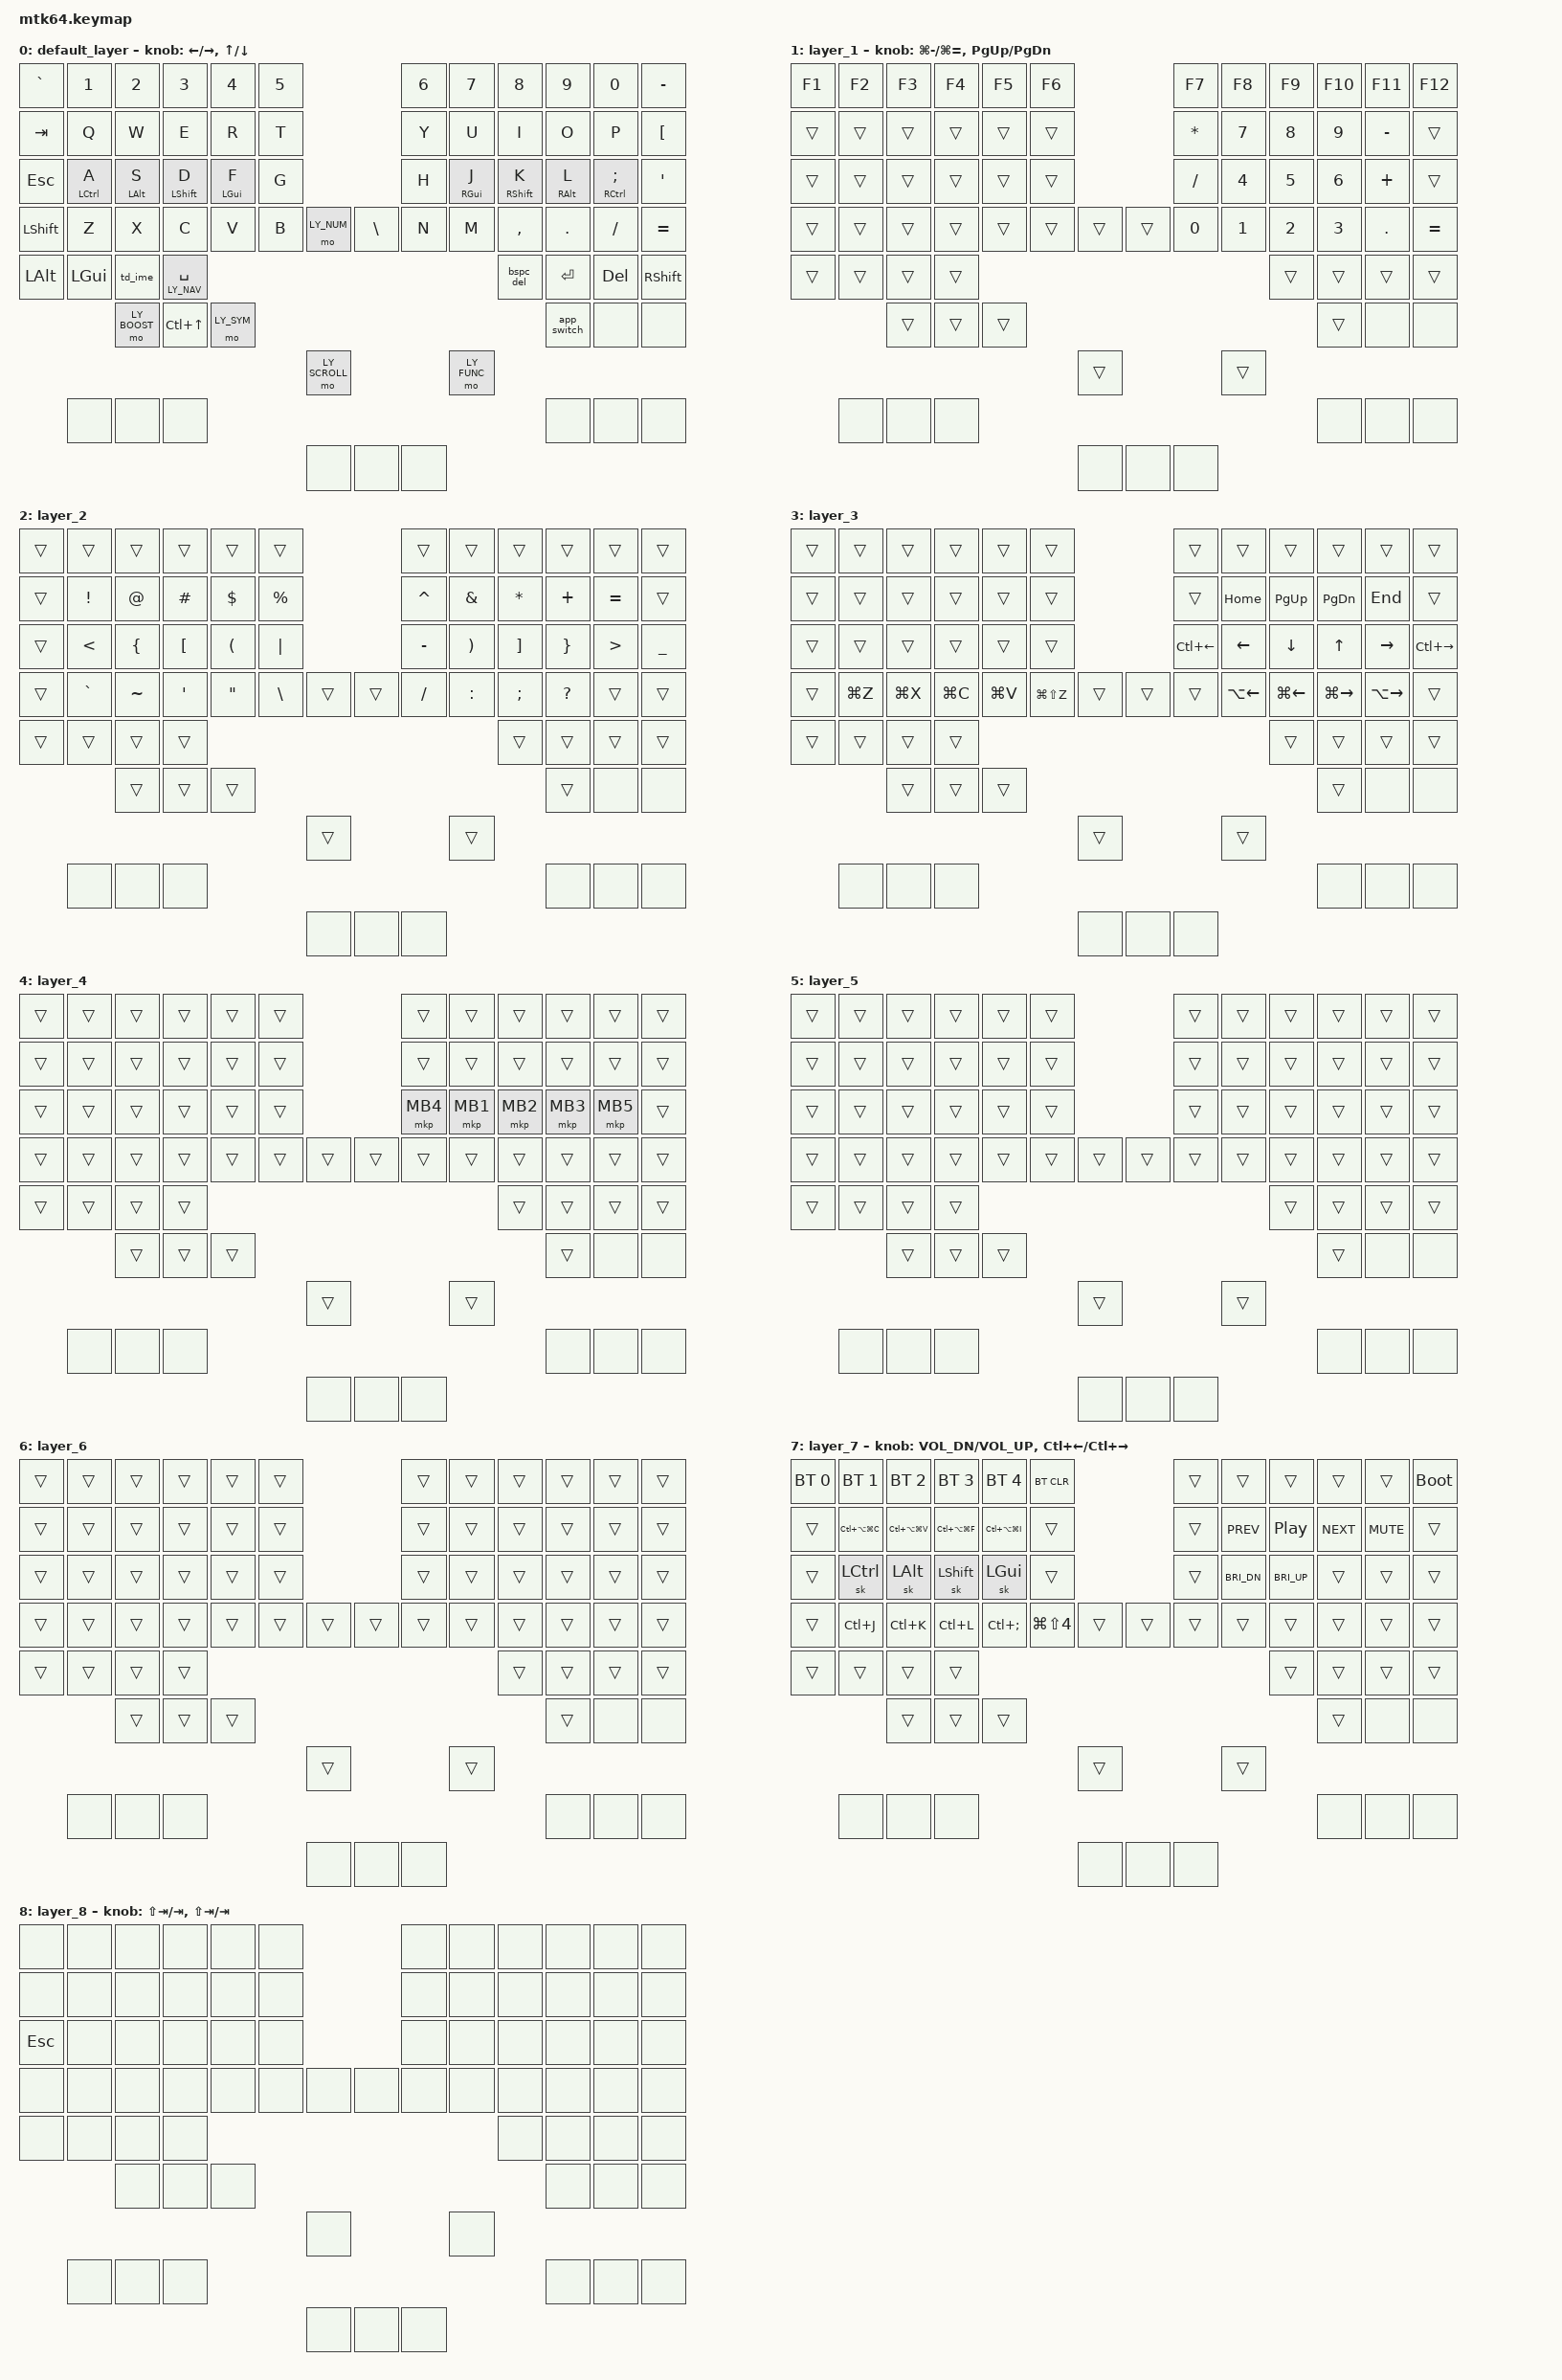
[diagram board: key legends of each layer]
// ポインタ既定値。dt-bindings/zmk/pointing.h の #include より「前」に置く必要がある。
// 後ろに書くと define が効かず、既定値 (MOVE=600 / SCRL=10) のままになる。
// 2026-08-13 まで9行目 (include の後ろ) にあったためスクロールが 10 で動いていた。
#define ZMK_POINTING_DEFAULT_MOVE_VAL 600
// SCRL_VAL は「1秒あたりのスクロール量」。エンコーダーは tap-ms 20ms 押す扱いなので
// 1目盛あたり SCRL_VAL × 0.02 が出る。100 なら 1目盛 = 2ノッチ。
// 800 も試したが速すぎたので戻した (2026-08-13)。
#define ZMK_POINTING_DEFAULT_SCRL_VAL 100

#include <behaviors.dtsi>
#include <dt-bindings/zmk/bt.h>
#include <dt-bindings/zmk/keys.h>
#include <dt-bindings/zmk/modifiers.h>
#include <dt-bindings/zmk/pointing.h>
#include <input/processors.dtsi>

// ============================================================
// レイヤー8枚 (2026-08-16, 工程2)
// 番号は mtk64_trackball.dtsi の zip_temp_layer / snipe / scroll とも一致させること。
// 片方だけ直すと、マウスもスクロールも精密モードも別のレイヤーを見にいく。
// ============================================================
#define LY_BASE   0
#define LY_NUM    1
#define LY_SYM    2
#define LY_NAV    3
#define LY_MOUSE  4
#define LY_SCROLL 5
#define LY_BOOST  6
#define LY_FUNC   7
#define LY_APPSW  8

&mt {
    flavor = "balanced";
    quick-tap-ms = <0>;
};

// マウスキーを押したときも自動マウスレイヤーに入る。番号は下の LY_MOUSE と同じ。
&mkp_input_listener {
    input-processors = <&zip_temp_layer LY_MOUSE 5000>;
};

/ {
    behaviors {
        // 垂直スクロール用のbehaviorの設定
        scroll_up_down: behavior_sensor_rotate_mouse_wheel_up_down {
            compatible = "zmk,behavior-sensor-rotate-var";
            #sensor-binding-cells = <2>;
            bindings = <&msc>, <&msc>;
            tap-ms = <20>; // スクロールのタップ時間
        };
        // 水平スクロール用のbehaviorの設定
        scroll_left_right: behavior_sensor_rotate_mouse_wheel_left_right {
            compatible = "zmk,behavior-sensor-rotate-var";
            #sensor-binding-cells = <2>;
            bindings = <&msc>, <&msc>;
            tap-ms = <20>; // スクロールのタップ時間
        };
    };
};

// ============================================================
// Home Row Mods (Phase 2-A, 2026-07-03 / 並びを 2026-08-13 に旧配列へ戻した) — urob流 timeless HRM
// 配列: 小指=Ctrl 薬指=Alt 中指=Shift 人差指=Cmd
//   (a=Ctrl s=Alt d=Shift f=Cmd / 右手ミラー j=Cmd k=Shift l=Alt ;=Ctrl)
//   Cmd+C/V/X/Z/A/S/W/T/F は文字がすべて左手にあり、バイラテラルでは必ず右手の Cmd を使う。
//   人差指 (J) に Cmd を置くと右手で最も強い指が使える。GACS では小指 (;) だった。
//   behavior のパラメータ (balanced / 280ms / 175ms / 150ms / バイラテラル) は変えていない。
// バイラテラル: hold-trigger-key-positions に「反対手 + 全親指」のみ列挙
//   → 同じ手のキーとの組合せでは自動的に tap 扱い (誤発火の構造的排除)
//
// require-prior-idle-ms = 150 の副作用: 直前150ms 以内に打鍵があると hold が発火せず tap になる。
//   つまり語中の大文字 (DX / FOB のような綴り) は HRM の Shift では打てない。
//   位置36 の物理 Shift を残してあるのはこの逃げ道のため。同じ理由で 50 (Alt) と 51 (Cmd) も残す
//   (Cmd+クリック / Shift+クリックは、HRM だと押しっぱなしが要るので物理キーのほうが確実)。
//   潰したのは位置24 の物理 Ctrl だけ。真下の a が HRM で Ctrl を持っていて完全に重複しており、
//   しかも Caps Lock 位置という一等地だったので Esc に回した (2026-08-16)。
//
// 物理の位置番号 (0起点、bindings 記載順):
//   Row1:  0-5   | 6-11      Row2: 12-17 | 18-23
//   Row3: 24-29  | 30-35     Row4: 36-42 | 43-49
//   Row5-7: 50-65             サイド/フット: 66-74
//   実在するキーは64個。名前の MTK64 と一致する。存在しないのは次の11か所:
//     58 / 59 = 左手のロータリーエンコーダー2個。押し込みは入力として使える (キーではない)
//     62 / 63 = トラックボール。キーが無いので押し込みも割り当てられない → &none
//     66-74   = 下端3キー×2・フットスイッチ3個。物理的に付いていない → &none
//   マトリクスの数だけは75個 合わせる必要がある。
// ============================================================
/ {
    behaviors {
        // 左手 HRM: 右手キー (6-11,18-23,30-35,43-49) + 親指 (50-65) とのみ hold 成立
        hml: homerow_mod_left {
            compatible = "zmk,behavior-hold-tap";
            #binding-cells = <2>;
            flavor = "balanced";
            tapping-term-ms = <280>;
            quick-tap-ms = <175>;
            require-prior-idle-ms = <150>;
            bindings = <&kp>, <&kp>;
            hold-trigger-key-positions = <6 7 8 9 10 11 18 19 20 21 22 23 30 31 32 33 34 35 43 44 45 46 47 48 49 50 51 52 53 54 55 56 57 58 59 60 61 62 63 64 65>;
            hold-trigger-on-release;
        };
        // 右手 HRM: 左手キー (0-5,12-17,24-29,36-42) + 親指 (50-65) とのみ hold 成立
        hmr: homerow_mod_right {
            compatible = "zmk,behavior-hold-tap";
            #binding-cells = <2>;
            flavor = "balanced";
            tapping-term-ms = <280>;
            quick-tap-ms = <175>;
            require-prior-idle-ms = <150>;
            bindings = <&kp>, <&kp>;
            hold-trigger-key-positions = <0 1 2 3 4 5 12 13 14 15 16 17 24 25 26 27 28 29 36 37 38 39 40 41 42 50 51 52 53 54 55 56 57 58 59 60 61 62 63 64 65>;
            hold-trigger-on-release;
        };

        // td_ime — 位置52。1タップ=英数 / 2タップ=かな (2026-08-16 に本人の希望で入れた)。
        //   ZMK の tap-dance は長押しを兼ねられない。bindings に <&lt_ime LY_SYM LANG2> を
        //   入れれば形は作れるが、tap-dance の200ms が解決してから hold-tap の180ms が
        //   始まるので、記号レイヤーに入るまで380ms かかる。入れ子にはしない。
        //   そのぶん SYM は位置60 の純粋な &mo に移した。長押し待ちが無くなるので、
        //   前の版で工程3送りにしていた「SYM に入るのに最大180ms」はこれで消えている。
        //
        //   1タップの確定は「tapping-term が切れる」か「別のキーが押される」かのどちらか早いほう。
        //   IME を切り替えたら必ず何か打つので、実際には次の1打鍵で即 確定する。
        //   200ms はダブルタップとみなす窓でもある。英数を2回 続けて叩くとかなになる点だけ注意。
        td_ime: tap_dance_ime {
            compatible = "zmk,behavior-tap-dance";
            #binding-cells = <0>;
            tapping-term-ms = <200>;
            bindings = <&kp LANG2>, <&kp LANG1>;
        };
        // lt_nav — Space (53)。Space は必ず文字の直後に来るので、require-prior-idle-ms が
        //   打鍵中の hold 誤発火を丸ごと止める。止まった後に押した時だけ balanced が効いて即座に
        //   NAV に入れる。矢印は連続して押すので、入るのが速いほうが得。
        lt_nav: layer_tap_nav {
            compatible = "zmk,behavior-hold-tap";
            #binding-cells = <2>;
            flavor = "balanced";
            tapping-term-ms = <200>;
            quick-tap-ms = <175>;
            require-prior-idle-ms = <150>;
            bindings = <&mo>, <&kp>;
        };

        // app_switch — 位置58 (外側のノブの押し込み)。Cmd+Tab のアプリ切替を
        //   ノブで送るためのもの (2026-08-16 の依頼)。押している間だけ Cmd を押しっぱなしにし、
        //   同時に LY_APPSW へ入る。そのレイヤーではエンコーダーが Tab / Shift+Tab を送るので、
        //   切替の一覧が開いたまま前にも後ろにも送れる。離すと Cmd が上がって確定する。
        //
        //   エンコーダーに直接 <&inc_dec_kp LG(LS(TAB)) LG(TAB)> を置くのでは駄目である。
        //   1目盛ごとに Cmd を離してしまうので、macOS はそのたびに切替を確定してしまい、
        //   一覧が開かない。2つのアプリを行ったり来たりするだけになる。
        //
        //   2026-08-17 に位置59 から58 へ移した。59 は Mission Control にしたため。
        //   押し込みながら回せるかは実機で確かめること。どちらのノブを回しても効くように、
        //   LY_APPSW ではエンコーダー2個に同じ割当を入れてある。
        //   型は ZMK 公式ドキュメント (keymaps/behaviors/macros) の「レイヤー + 修飾キー」そのもの。
        app_switch: app_switch {
            compatible = "zmk,behavior-macro";
            #binding-cells = <0>;
            wait-ms = <0>;
            tap-ms = <0>;
            bindings
                = <&macro_press &mo LY_APPSW &kp LGUI>
                , <&macro_pause_for_release>
                , <&macro_release &mo LY_APPSW &kp LGUI>;
        };

        // BkSp を Shift と一緒に押すと Delete (前方削除)。遅延ゼロ。
        // 位置56 にも独立した Delete を置いてあるので、どちらでも打てる。
        bspc_del: backspace_delete {
            compatible = "zmk,behavior-mod-morph";
            #binding-cells = <0>;
            bindings = <&kp BSPC>, <&kp DEL>;
            mods = <(MOD_LSFT|MOD_RSFT)>;
        };
    };

    // 句読点 combo — 旧 Studio カスタム (j長押し=、 k長押し=。 ;長押し=ー) の置換。
    // 長押し待ち (200ms) がなくなり同時押しで即入力。ローマ字入力で j+k / k+l / l+; の
    // ロールはほぼ発生しないため誤爆リスク低 (英語 "quickly" 等の k→l ロールだけ Week1 で観測)
    combos {
        compatible = "zmk,combos";
        combo_touten {
            timeout-ms = <30>;
            key-positions = <31 32>;    // J + K → 、
            bindings = <&kp COMMA>;
            layers = <0>;
        };
        combo_kuten {
            timeout-ms = <30>;
            key-positions = <32 33>;    // K + L → 。
            bindings = <&kp DOT>;
            layers = <0>;
        };
        combo_chouon {
            timeout-ms = <30>;
            key-positions = <33 34>;    // L + ; → ー
            bindings = <&kp MINUS>;
            layers = <0>;
        };
        // F + J で次の1語だけ大文字 (Caps Word)。Shift を押しっぱなしにしないで済む。
        // 左右にまたがるので同じ手のロールでは起きない。f→j / j→f はローマ字にも英語にも無い。
        combo_caps_word {
            timeout-ms = <30>;
            key-positions = <28 31>;    // F + J
            bindings = <&caps_word>;
            layers = <0>;
        };
    };
};

/ {

    keymap {
        compatible = "zmk,keymap";

        // ------------------------------------------------------------------
        // L0 BASE — US ANSI QWERTY + Home Row Mods
        //   0  : ` (バッククォート)。工程1 まで7レイヤー525キーのどこにも無かった字。
        //         Markdown のコードスパンで毎日使うので US ANSI の定位置に置いた。
        //   24 : Esc。Caps Lock 位置。日本語入力の変換取り消しで最も打つキーなので一等地に移した。
        //   49 : = 。工程1 まで死んでいた位置。右小指の外側の列が上から - [ ' = で揃う。
        //   56 : Delete (前方削除)。工程1 まで keymap 全体に1つも無かった。
        //   57 : 右手の物理 Shift。工程1 まで右半分には物理の修飾キーが1つも無かった。
        //         左手の文字を語中で大文字にする (DX / FOB) には右手の Shift が要るのに、
        //         HRM の k は require-prior-idle-ms で打鍵中は発火しない。50/51 の鏡の位置。
        //   54 : BkSp / Shift併用で Delete (mod-morph)。
        //   58 / 59 : ロータリーエンコーダーの押し込み (2026-08-17 に入れ替えた)。
        //         58 (外側) = アプリ切替。押したまま回すと Cmd+Tab の一覧を送れる (app_switch を見よ)。
        //         59 (内側) = Mission Control (Ctrl+↑)。本人の希望で入れた。
        //         ミュートはここから外したが FUNC の段1 (位置15) に残っている。
        //         Enter は 55 の右親指に1つ残っている。
        //   42 : NUM の呼び出し (左手人差指の内側)。親指4本が IME・Space・SYM・SCROLL で
        //         埋まったので、テンキーだけ指に降ろした。右手でテンキーを打つので hold は左手が要る。
        //         ここにあった ] は SYM の K で打てるので BASE からは落とした。
        //   52 : 1タップ=英数 / 2タップ=かな (tap_dance)。長押しは無い。
        //   60 : SYM。純粋な &mo なので長押し待ちがゼロ。ここは かな だった。
        // ------------------------------------------------------------------
        default_layer {
            bindings = <
&kp GRAVE &kp N1       &kp N2       &kp N3        &kp N4       &kp N5                            &kp N6 &kp N7      &kp N8       &kp N9      &kp N0           &kp MINUS
&kp TAB   &kp Q        &kp W        &kp E         &kp R        &kp T                             &kp Y  &kp U       &kp I        &kp O       &kp P            &kp LBKT
&kp ESC   &hml LCTRL A &hml LALT S  &hml LSHFT D  &hml LGUI F  &kp G                             &kp H  &hmr RGUI J &hmr RSHFT K &hmr RALT L &hmr RCTRL SEMI  &kp SQT
&kp LSHFT &kp Z        &kp X        &kp C         &kp V        &kp B        &mo LY_NUM  &kp BSLH &kp N  &kp M       &kp COMMA    &kp DOT     &kp SLASH        &kp EQUAL
&kp LALT  &kp LGUI                                &td_ime          &lt_nav LY_NAV SPACE      &bspc_del &kp ENTER                                  &kp DEL          &kp RSHFT
                       &mo LY_BOOST               &kp LC(UP)                &mo LY_SYM                &app_switch                          &none       &none
                                                                            &mo LY_SCROLL             &mo LY_FUNC
          &none        &none        &none                                                                                       &none       &none            &none
                                                                            &none    &none       &none
            >;

            // 2026-08-17 に頻度で並べ替えた。BASE で最も回すのはカーソル移動なのでここに置く。
            // 音量は FUNC へ、デスクトップ切り替えは NAV へ移した。
            sensor-bindings = <
                &inc_dec_kp LEFT_ARROW RIGHT_ARROW
                &inc_dec_kp UP_ARROW   DOWN_ARROW
            >;
        };

        // ------------------------------------------------------------------
        // L1 NUM — 左親指60 (かな) の長押し
        //   右手にテンキー。左手の上段は F1〜F12、ホームローは &trans なので HRM が生きている。
        //   つまり NUM を押したまま f (Cmd) + 5 で Cmd+5 が打てる。
        // ------------------------------------------------------------------
        layer_1 {
            bindings = <
&kp F1  &kp F2  &kp F3  &kp F4  &kp F5  &kp F6                      &kp F7        &kp F8  &kp F9  &kp F10 &kp F11    &kp F12
&trans  &trans  &trans  &trans  &trans  &trans                      &kp ASTRK     &kp N7  &kp N8  &kp N9  &kp MINUS  &trans
&trans  &trans  &trans  &trans  &trans  &trans                      &kp FSLH      &kp N4  &kp N5  &kp N6  &kp PLUS   &trans
&trans  &trans  &trans  &trans  &trans  &trans  &trans      &trans  &kp N0        &kp N1  &kp N2  &kp N3  &kp DOT    &kp EQUAL
&trans  &trans                          &trans  &trans      &trans  &trans                        &trans  &trans
                &trans  &trans                  &trans      &trans                        &none   &none
                                                &trans      &trans
        &none   &none   &none                                                             &none   &none   &none
                                                &none  &none  &none
            >;
            sensor-bindings = <
                &inc_dec_kp LG(MINUS) LG(EQUAL)
                &inc_dec_kp PG_UP PG_DN
            >;
        };

        // ------------------------------------------------------------------
        // L2 SYM — 左親指52 (英数) の長押し
        //   上段は Shift+数字の並びをそのまま下ろした ! @ # $ % ^ & * 。最後の2つだけ + = に替えてある
        //   (( ) はホームローに置いたので重複させない)。
        //   ホームローは開き括弧を左手・閉じ括弧を右手に、指で鏡写しにした。
        //     A< S{ D[ F( G|  ／  H- J) K] L} ;> '_
        //   数字段は &trans なので、SYM を押したまま数字が打てる ($100 のような並び用)。
        //   修飾キーは物理の 36 (Shift) / 50 (Alt) / 51 (Cmd) が &trans で生きている。
        // ------------------------------------------------------------------
        layer_2 {
            bindings = <
&trans  &trans     &trans     &trans     &trans     &trans                        &trans      &trans     &trans     &trans     &trans    &trans
&trans  &kp EXCL   &kp AT     &kp HASH   &kp DLLR   &kp PRCNT                     &kp CARET   &kp AMPS   &kp ASTRK  &kp PLUS   &kp EQUAL &trans
&trans  &kp LT     &kp LBRC   &kp LBKT   &kp LPAR   &kp PIPE                      &kp MINUS   &kp RPAR   &kp RBKT   &kp RBRC   &kp GT    &kp UNDER
&trans  &kp GRAVE  &kp TILDE  &kp SQT    &kp DQT    &kp BSLH   &trans     &trans  &kp FSLH    &kp COLON  &kp SEMI   &kp QMARK  &trans    &trans
&trans  &trans                                      &trans     &trans     &trans  &trans                            &trans     &trans
                   &trans     &trans                           &trans     &trans                         &none      &none
                                                               &trans     &trans
        &none      &none      &none                                                           &none      &none      &none
                                                               &none  &none  &none
            >;
            // エンコーダーの割当は置かない。SYM は位置60 の左手 親指で呼ぶが、
            // その親指がノブを回すので同時に成立しない (2026-08-17 に判明)。
            // 書かなければ BASE の矢印に落ちる。
        };

        // ------------------------------------------------------------------
        // L3 NAV — 左親指53 (Space) の長押し
        //   右手を列でそろえてある。上から順に「大きく飛ぶ / 1つ動く / 単語と行の端」。
        //     列14: Home  ← Opt+←(単語左)     列15: PgUp ↓ Cmd+←(行頭)
        //     列16: PgDn  ↑ Cmd+→(行末)       列17: End  → Opt+→(単語右)
        //   左手の Z X C V B に取り消し・切り取り・コピー・貼り付け・やり直し。
        //   親指64/65 から外した Cmd+C / Cmd+V はここに戻っている。
        //   左手のホームローは &trans なので、d (HRM Shift) を押しながら右手の矢印で選択できる。
        //   HRM が効かないときは位置36 の物理 Shift を使う。
        //
        //   ※ 工程1 までこのレイヤーは3行目が14個 (row4 の形) で書かれていて、位置24 以降が
        //     2つずつ後ろにずれていた。ずれた先が全部 &trans だったので出力は変わっていなかったが、
        //     ここで正しい 12/12/12/14/8/6/2/9 に組み直した。
        // ------------------------------------------------------------------
        layer_3 {
            bindings = <
&trans  &trans        &trans        &trans        &trans        &trans                        &trans  &trans        &trans        &trans        &trans        &trans
&trans  &trans        &trans        &trans        &trans        &trans                        &trans  &kp HOME      &kp PG_UP     &kp PG_DN     &kp END       &trans
&trans  &trans        &trans        &trans        &trans        &trans                        &kp LC(LEFT)  &kp LEFT  &kp DOWN  &kp UP    &kp RIGHT     &kp LC(RIGHT)
&trans  &kp LG(Z)     &kp LG(X)     &kp LG(C)     &kp LG(V)     &kp LG(LS(Z))  &trans  &trans  &trans  &kp LA(LEFT)  &kp LG(LEFT)  &kp LG(RIGHT) &kp LA(RIGHT) &trans
&trans  &trans                                    &trans        &trans         &trans  &trans                                     &trans        &trans
                      &trans        &trans                                     &trans  &trans                       &none         &none
                                                                               &trans  &trans
        &none         &none         &none                                                                           &none         &none         &none
                                                                               &none  &none  &none
            >;
            // エンコーダーの割当は置かない。NAV は位置53 の左手 親指で呼ぶが、
            // その親指がノブを回すので同時に成立しない。デスクトップ切り替えは FUNC へ移した。
        };

        // ------------------------------------------------------------------
        // L4 MOUSE — トラックボールが動くと zip_temp_layer で自動的に入る
        //   クリックは右手ホームロー。2026-08-16 に本人が実機で確かめた
        //   「ボールを転がしたまま J を押し続けて範囲選択ができる」ので、右手のまま据え置く。
        //   ここを動かしたら mtk64_trackball.dtsi の excluded-positions も必ず追随させる
        //   (excluded-positions に無いキーを押すとレイヤーが解除されてクリックにならない)。
        // ------------------------------------------------------------------
        layer_4 {
            bindings = <
&trans  &trans  &trans  &trans  &trans  &trans                      &trans    &trans    &trans    &trans    &trans    &trans
&trans  &trans  &trans  &trans  &trans  &trans                      &trans    &trans    &trans    &trans    &trans    &trans
&trans  &trans  &trans  &trans  &trans  &trans                      &mkp MB4  &mkp MB1  &mkp MB2  &mkp MB3  &mkp MB5  &trans
&trans  &trans  &trans  &trans  &trans  &trans  &trans      &trans  &trans    &trans    &trans    &trans    &trans    &trans
&trans  &trans                          &trans  &trans      &trans  &trans                        &trans    &trans
                &trans  &trans                  &trans      &trans                      &none     &none
                                                &trans      &trans
        &none   &none   &none                                                           &none     &none     &none
                                                &none  &none  &none
            >;
        };

        // ------------------------------------------------------------------
        // L5 SCROLL — 左親指64 を押している間だけ、ボールが縦横スクロールになる
        //   全キー &trans。MOUSE (L4) より上なので、押している間もクリックは下に落ちて効く。
        //   エンコーダーは1個目が縦・2個目が横。
        // ------------------------------------------------------------------
        layer_5 {
            bindings = <
&trans  &trans  &trans  &trans  &trans  &trans                      &trans  &trans  &trans  &trans  &trans  &trans
&trans  &trans  &trans  &trans  &trans  &trans                      &trans  &trans  &trans  &trans  &trans  &trans
&trans  &trans  &trans  &trans  &trans  &trans                      &trans  &trans  &trans  &trans  &trans  &trans
&trans  &trans  &trans  &trans  &trans  &trans  &trans      &trans  &trans  &trans  &trans  &trans  &trans  &trans
&trans  &trans                          &trans  &trans      &trans  &trans                  &trans  &trans
                &trans  &trans                  &trans      &trans                  &none   &none
                                                &trans      &trans
        &none   &none   &none                                                       &none   &none   &none
                                                &none  &none  &none
            >;
            // エンコーダーの割当は置かない。SCROLL は位置64 の左手 親指で呼ぶが、
            // その親指がノブを回すので同時に成立しない。スクロールはボールでやる。
        };

        // ------------------------------------------------------------------
        // L6 SNIPE — 右親指61 を押している間だけ、ボールの分解能が落ちて精密になる
        //   全キー &trans。MOUSE (L4) より上なので、押している間もクリックは下に落ちて効く。
        // ------------------------------------------------------------------
        layer_6 {
            bindings = <
&trans  &trans  &trans  &trans  &trans  &trans                      &trans  &trans  &trans  &trans  &trans  &trans
&trans  &trans  &trans  &trans  &trans  &trans                      &trans  &trans  &trans  &trans  &trans  &trans
&trans  &trans  &trans  &trans  &trans  &trans                      &trans  &trans  &trans  &trans  &trans  &trans
&trans  &trans  &trans  &trans  &trans  &trans  &trans      &trans  &trans  &trans  &trans  &trans  &trans  &trans
&trans  &trans                          &trans  &trans      &trans  &trans                  &trans  &trans
                &trans  &trans                  &trans      &trans                  &none   &none
                                                &trans      &trans
        &none   &none   &none                                                       &none   &none   &none
                                                &none  &none  &none
            >;
        };

        // ------------------------------------------------------------------
        // L7 FUNC — 右親指65 を押している間
        //   右親指で呼ぶので、中身は全部 左手に置いてある。唯一の例外は位置11 の &bootloader で、
        //   これは同じ手の小指を上まで伸ばさないと届かない＝誤爆しない位置に置いてある。
        //   段1: 左手にアプリ切り替え4つ、右手にメディア4つ（音量と明るさはノブ側にある）
        //   段2: 固定修飾 (&sk。手首が痛む日に押しっぱなしを避ける逃げ道)
        //   段3: ことえりの変換やり直しとスクリーンショット
        //     Ctrl+J ひらがな / Ctrl+K カタカナ / Ctrl+L 全角英数 / Ctrl+; 半角英数
        //     いずれも &kp 1つで書けるので ZMK のマクロは使っていない。
        //
        //   アプリ切り替え (13-16) は Ctrl+Opt+Cmd+<文字> を送るだけである。
        //   **キーボード単体では動かない。** アプリを前面に出すのは OS の仕事で、
        //   ファームウェアはキーコードしか送れない。macOS 標準の ショートカット.app に
        //   「Appを開く」だけのショートカットを4つ作り、それぞれに次の組合せを割り当てること。
        //     Ctrl+Opt+Cmd+C = Google Chrome   (実測 29日で 194.1時間)
        //     Ctrl+Opt+Cmd+V = Visual Studio Code (71.6時間)
        //     Ctrl+Opt+Cmd+F = Finder          (8.4時間)
        //     Ctrl+Opt+Cmd+I = Illustrator     (6.8時間)
        //   BTT や Raycast は要らない。ショートカット.app は OS 標準なので
        //   シャドーIT の審査対象にならない。並びは実測の時間順で、文字は頭文字である。
        // ------------------------------------------------------------------
        layer_7 {
            bindings = <
&bt BT_SEL 0 &bt BT_SEL 1     &bt BT_SEL 2     &bt BT_SEL 3     &bt BT_SEL 4     &bt BT_CLR                    &trans  &trans  &trans  &trans  &trans  &bootloader
&trans       &kp LC(LA(LG(C))) &kp LC(LA(LG(V))) &kp LC(LA(LG(F))) &kp LC(LA(LG(I))) &trans                &trans  &kp C_PREV  &kp C_PP  &kp C_NEXT  &kp C_MUTE  &trans
&trans       &sk LCTRL        &sk LALT         &sk LSHFT        &sk LGUI         &trans                        &trans  &kp C_BRI_DN  &kp C_BRI_UP  &trans  &trans  &trans
&trans       &kp LC(J)        &kp LC(K)        &kp LC(L)        &kp LC(SEMI)     &kp LG(LS(N4)) &trans  &trans  &trans  &trans  &trans  &trans  &trans  &trans
&trans       &trans                                 &trans       &trans         &trans  &trans                  &trans  &trans
                          &trans       &trans                                   &trans  &trans          &none   &none
                                                                                &trans  &trans
        &none             &none        &none                                                            &none   &none   &none
                                                                                &none  &none  &none
            >;
            // FUNC は位置65 の右手 親指で呼ぶので、左手の親指でノブを回せる。
            // エンコーダーを使えるレイヤーは NUM(42 左人差指) と FUNC(65 右親指) と
            // アプリ切替(61 右親指) の3枚だけである。
            // 2個目はデスクトップ切り替え。NAV から移した (NAV では押しながら回せない)。
            // 明るさはキー側 (段2 右の 31・32) に移した。
            sensor-bindings = <
                &inc_dec_kp C_VOL_DN C_VOL_UP
                &inc_dec_kp LC(LEFT_ARROW) LC(RIGHT_ARROW)
            >;
        };

        // ------------------------------------------------------------------
        // L8 APPSW — 位置59 (エンコーダーの押し込み) を押している間だけ
        //   app_switch マクロが Cmd を押しっぱなしにしたまま、ここへ入れる。
        //   ノブを回すと Cmd+Tab / Cmd+Shift+Tab が飛ぶので、切替の一覧を送れる。
        //   左右どちらのノブでも効くようにエンコーダー2個へ同じ割当を入れてある。
        //
        //   キーは Esc だけを残して全部 &none にしてある。&trans にすると Cmd が
        //   押しっぱなしのまま下の BASE が生きるので、うっかり触った文字が
        //   Cmd+Q や Cmd+W になる。Esc は macOS で切替の取り消しになる。
        // ------------------------------------------------------------------
        layer_8 {
            bindings = <
&none    &none  &none  &none  &none  &none                     &none  &none  &none  &none  &none  &none
&none    &none  &none  &none  &none  &none                     &none  &none  &none  &none  &none  &none
&kp ESC  &none  &none  &none  &none  &none                     &none  &none  &none  &none  &none  &none
&none    &none  &none  &none  &none  &none  &none      &none   &none  &none  &none  &none  &none  &none
&none    &none                        &none  &none     &none   &none                       &none  &none
                &none  &none                 &none     &none                 &none  &none
                                             &none     &none
        &none   &none  &none                                                 &none  &none  &none
                                             &none  &none  &none
            >;
            sensor-bindings = <
                &inc_dec_kp LS(TAB) TAB
                &inc_dec_kp LS(TAB) TAB
            >;
        };
    };
};
